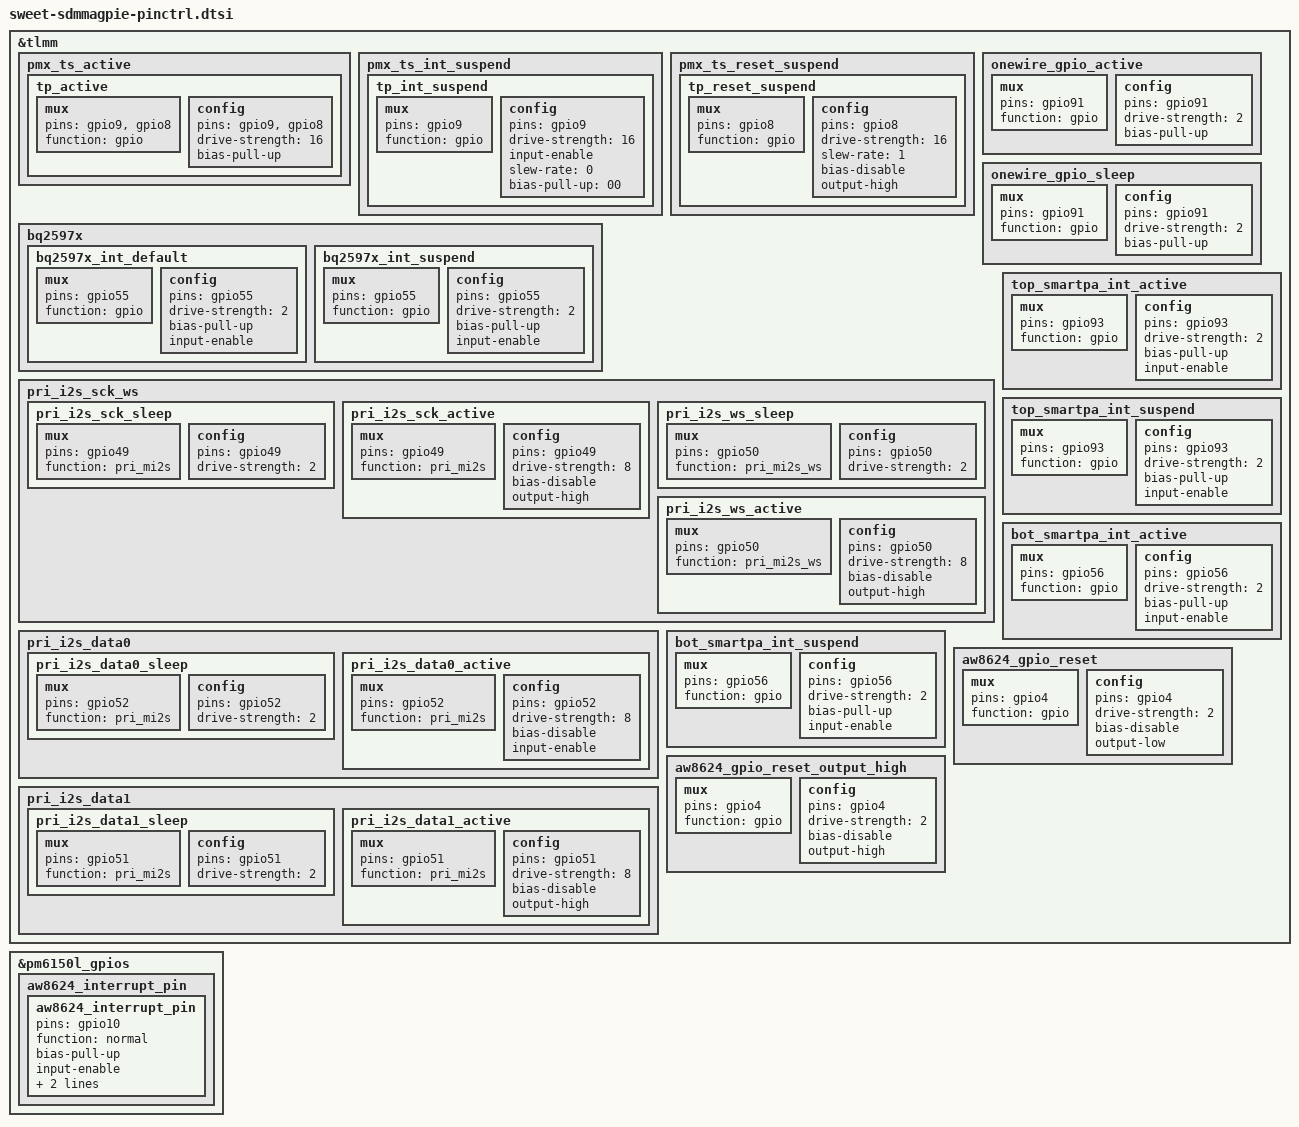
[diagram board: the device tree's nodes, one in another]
/*for K6 SM7150 pinctrl*/

&tlmm {
	/*touchpanel*/
	pmx_ts_active {
			tp_active: tp_active {
					mux {
						pins = "gpio9", "gpio8";
						function = "gpio";
					};
					config {
						pins = "gpio9", "gpio8";
						drive-strength = <16>;
						bias-pull-up;
					};
			};
	};

	pmx_ts_int_suspend {
			tp_int_suspend: tp_int_suspend {
				mux {
					pins = "gpio9";
					function = "gpio";
				};
				config {
					pins = "gpio9";
					drive-strength = <16>;
					input-enable;
					slew-rate = <0>;
					bias-pull-up = <00>;
				};
			};
	};

	pmx_ts_reset_suspend {
			tp_reset_suspend: tp_reset_suspend {
				mux {
					pins = "gpio8";
					function = "gpio";
				};
				config {
					pins = "gpio8";
					drive-strength = <16>;
					slew-rate = <1>;
					bias-disable;
					output-high;
				};
			};
	};
	bq2597x {
		bq2597x_int_default: bq2597x_int_default {
			/* active state */
			mux {
				/* GPIO 48 is used for bq25970 master ic interrupt usage */
				pins = "gpio55";
				function = "gpio";
			};

			config {
				pins = "gpio55";
				drive-strength = <2>; /* 2 MA */
				bias-pull-up;
				input-enable;
			};
		};

		bq2597x_int_suspend: bq2597x_int_suspend {
			/* sleep state */
			mux {
				/* GPIO 55 is used for bq25970 master ic interrupt usage */
				pins = "gpio55";
				function = "gpio";
			};

			config {
				pins = "gpio55";
				drive-strength = <2>; /* 2 MA */
				bias-pull-up;
				input-enable;
			};
		};
	};

	onewire_gpio_active: onewire_gpio_active {
		mux {
			pins = "gpio91";
			function = "gpio";
		};

		config {
			pins = "gpio91";
			drive-strength = <2>;
			bias-pull-up; /* No PULL */
		};
	};

	onewire_gpio_sleep: onewire_gpio_sleep {
		mux {
			pins = "gpio91";
			function = "gpio";
		};

		config {
			pins = "gpio91";
			drive-strength = <2>;
			bias-pull-up;
		};
	};

	pri_i2s_sck_ws {
		pri_i2s_sck_sleep: pri_i2s_sck_sleep {
			mux {
				pins = "gpio49";
				function = "pri_mi2s";
			};

			config {
				pins = "gpio49";
				drive-strength = <2>;   /* 2 mA */
			};
		};

		pri_i2s_sck_active: pri_i2s_sck_active {
			mux {
				pins = "gpio49";
				function = "pri_mi2s";
			};

			config {
				pins = "gpio49";
				drive-strength = <8>;   /* 8 mA */
				bias-disable;
				output-high;
			};
		};

		pri_i2s_ws_sleep: pri_i2s_ws_sleep {
			mux {
				pins = "gpio50";
				function = "pri_mi2s_ws";
			};

			config {
				pins = "gpio50";
				drive-strength = <2>;   /* 2 mA */
			};
		};

		pri_i2s_ws_active: pri_i2s_ws_active {
			mux {
				pins = "gpio50";
				function = "pri_mi2s_ws";
			};

			config {
				pins = "gpio50";
				drive-strength = <8>;   /* 8 mA */
				bias-disable;
				output-high;
			};
		};
	};

	pri_i2s_data0 {
		pri_i2s_data0_sleep: pri_i2s_data0_sleep {
			mux {
				pins = "gpio52";
				function = "pri_mi2s";
			};

			config {
				pins = "gpio52";
				drive-strength = <2>;   /* 2 mA */
			};
		};

		pri_i2s_data0_active: pri_i2s_data0_active {
			mux {
				pins = "gpio52";
				function = "pri_mi2s";
			};

			config {
				pins = "gpio52";
				drive-strength = <8>;   /* 8 mA */
				bias-disable;
				input-enable;
			};
		};
	};

	pri_i2s_data1 {
		pri_i2s_data1_sleep: pri_i2s_data1_sleep {
			mux {
				pins = "gpio51";
				function = "pri_mi2s";
			};

			config {
				pins = "gpio51";
				drive-strength = <2>;   /* 2 mA */
			};
		};

		pri_i2s_data1_active: pri_i2s_data1_active {
			mux {
				pins = "gpio51";
				function = "pri_mi2s";
			};

			config {
				pins = "gpio51";
				drive-strength = <8>;   /* 8 mA */
				bias-disable;
				output-high;
			};
		};
	};

	top_smartpa_int_active: top_smartpa_int_active {
		/* active state */
		mux {
			/* GPIO 93 Interrupt */
			pins = "gpio93";
			function = "gpio";
		};

		config {
			pins = "gpio93";
			drive-strength = <2>; /* 2 MA */
			bias-pull-up;
			input-enable;
		};
	};

	top_smartpa_int_suspend: top_smartpa_int_suspend {
		/* sleep state */
		mux {
			/* GPIO 93 Interrupt */
			pins = "gpio93";
			function = "gpio";
		};

		config {
			pins = "gpio93";
			drive-strength = <2>; /* 2 MA */
			bias-pull-up;
			input-enable;
		};
	};

	bot_smartpa_int_active: bot_smartpa_int_active {
		/* active state */
		mux {
			/* GPIO 56 Interrupt */
			pins = "gpio56";
			function = "gpio";
		};

		config {
			pins = "gpio56";
			drive-strength = <2>; /* 2 MA */
			bias-pull-up;
			input-enable;
		};
	};

	bot_smartpa_int_suspend: bot_smartpa_int_suspend {
		/* sleep state */
		mux {
			/* GPIO 56 Interrupt */
			pins = "gpio56";
			function = "gpio";
		};

		config {
			pins = "gpio56";
			drive-strength = <2>; /* 2 MA */
			bias-pull-up;
			input-enable;
		};
	};
	/* aw8624 RESET*/
	aw8624_gpio_reset: aw8624_gpio_reset {
		mux {
			pins="gpio4";
			function= "gpio";
		};
		config {
			pins= "gpio4";
			drive-strength = <2>;
			bias-disable;
			output-low;
		};
	};
	/* aw8624 Enable*/
	aw8624_gpio_reset_output_high: aw8624_gpio_reset_output_high {
		mux {
			pins="gpio4";
			function= "gpio";
		};
		config {
			pins= "gpio4";
			drive-strength = <2>; /* 2 mA */
			bias-disable;
			output-high;
		};
	};
};
/* AW8624_INTERRUPT */
&pm6150l_gpios {
	aw8624_interrupt_pin {
		aw8624_interrupt_pin: aw8624_interrupt_pin {
			pins = "gpio10";
			function = "normal";
			bias-pull-up;
			input-enable;
			power-source = <1>;
			qcom,pull-up-strength = <2>;
		};
	};
};

